# DA1470x register map
Vendor: Dialog; Series: DA1470x; File version: 1.2
CPU: CM33 r0p2, little endian, MPU, FPU, DSP, VTOR, 4 interrupt priority bits
Registers are 32-bit, read-write, reset 0x0 unless marked. A register's access mark holds for its fields unless they carry their own. Offsets are from the block's base; [hi:lo] are bit positions.

## GPREG — GPREG registers
Base 0x50040100
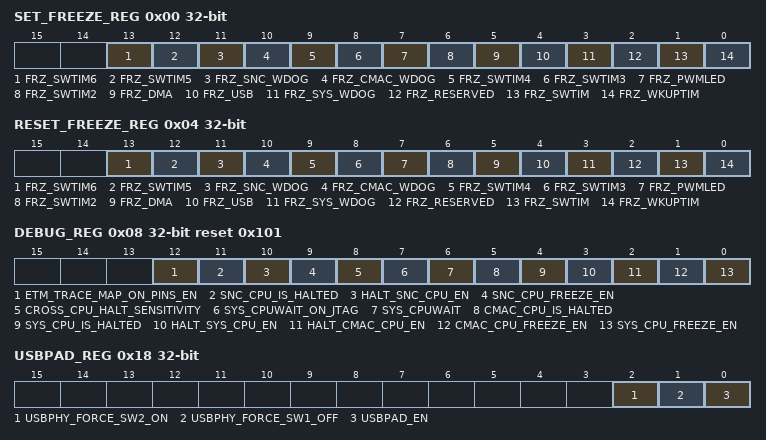
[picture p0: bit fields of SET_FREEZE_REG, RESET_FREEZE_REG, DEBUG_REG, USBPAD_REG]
0x00 SET_FREEZE_REG — Controls freezing of various timers/counters (incl. DMA and USB).
  [13] FRZ_SWTIM6 — If '1', the SW Timer6 is frozen, '0' is discarded.
  [12] FRZ_SWTIM5 — If '1', the SW Timer5 is frozen, '0' is discarded.
  [11] FRZ_SNC_WDOG — If '1', the SNC SW Watchdog Timer is frozen, '0' is discarded.
  [10] FRZ_CMAC_WDOG — If '1', the CMAC SW Watchdog Timer is frozen, '0' is discarded.
  [9] FRZ_SWTIM4 — If '1', the SW Timer4 is frozen, '0' is discarded.
  [8] FRZ_SWTIM3 — If '1', the SW Timer3 is frozen, '0' is discarded.
  [7] FRZ_PWMLED — If '1', the PWM LED is frozen, '0' is discarded.
  [6] FRZ_SWTIM2 — If '1', the SW Timer2 is frozen, '0' is discarded.
  [5] FRZ_DMA — If '1', the DMA is frozen, '0' is discarded.
  [4] FRZ_USB — If '1', the USB is frozen, '0' is discarded.
  [3] FRZ_SYS_WDOG — If '1', the SYS SW Watchdog Timer is frozen, '0' is discarded. WATCHDOG_CTRL_REG[NMI_RST] must be '0' to allow the freeze function.
  [2] FRZ_RESERVED
  [1] FRZ_SWTIM — If '1', the SW Timer is frozen, '0' is discarded.
  [0] FRZ_WKUPTIM — If '1', the Wake Up Timer is frozen, '0' is discarded.
0x04 RESET_FREEZE_REG — Controls unfreezing of various timers/counters (incl. DMA and USB).
  [13] FRZ_SWTIM6 — If '1', the SW Timer6 continues, '0' is discarded.
  [12] FRZ_SWTIM5 — If '1', the SW Timer5 continues, '0' is discarded.
  [11] FRZ_SNC_WDOG — If '1', the SNC SW Watchdog Timer continues, '0' is discarded.
  [10] FRZ_CMAC_WDOG — If '1', the CMAC SW Watchdog Timer continues, '0' is discarded.
  [9] FRZ_SWTIM4 — If '1', the SW Timer4 continues, '0' is discarded.
  [8] FRZ_SWTIM3 — If '1', the SW Timer3 continues, '0' is discarded.
  [7] FRZ_PWMLED — If '1', the PWM LED continues, '0' is discarded.
  [6] FRZ_SWTIM2 — If '1', the SW Timer2 continues, '0' is discarded.
  [5] FRZ_DMA — If '1', the DMA continues, '0' is discarded.
  [4] FRZ_USB — If '1', the USB continues, '0' is discarded.
  [3] FRZ_SYS_WDOG — If '1', the SYS SW Watchdog Timer continues, '0' is discarded.
  [2] FRZ_RESERVED
  [1] FRZ_SWTIM — If '1', the SW Timer continues, '0' is discarded.
  [0] FRZ_WKUPTIM — If '1', the Wake Up Timer continues, '0' is discarded.
0x08 DEBUG_REG reset 0x101 — Various debug information register.
  [12] ETM_TRACE_MAP_ON_PINS_EN — 1: ETM/TPIU Trace signals mapped on GPIO pins is enabled.
  [11] SNC_CPU_IS_HALTED ro — 1: SNC CPU is halted.
  [10] HALT_SNC_CPU_EN — 1: Enable halting the SNC CPU when the SYS CPU (ARM CM33) or CMAC CPU is halted. Note 1: This bit is retained. Note 2: Set this bit to '0' before going into deep sleep to prevent unpredictable halting behavior after waking up.
  [9] SNC_CPU_FREEZE_EN — 1: Enable Freezing on-chip peripherals (see Note 2) by the SNC CPU. Note 1: This bit is retained. Note 2: See [RE]SET_FREEZE_REG for the specific on-chip peripherals.
  [8] CROSS_CPU_HALT_SENSITIVITY — Select the cross CPU halt sensitivity. 0: Level triggered, 1: Pulse triggered. Note: This bit is retained.
  [7] SYS_CPUWAIT_ON_JTAG — 1: Stall the processor core out of reset (only after a wake-up from JTAG). Debugger access continue when the core is stalled. When set to '0' again the core resumes instruction execution. This feature is independent of the PDC (Power Domain Controller) settings. If this bit is set and there is SW/JTAG activity during deep sleep, the SYS CPU is stalled after the wake-up. Note: This bit is retained.
  [6] SYS_CPUWAIT — 1: Stall the processor core out of reset (always after a wake-up). Debugger access continue when the core is stalled. When set to '0' again the core resumes instruction execution. Note: This bit is retained.
  [5] CMAC_CPU_IS_HALTED ro — 1: CMAC CPU is halted.
  [4] SYS_CPU_IS_HALTED ro — 1: SYS CPU (ARM CM33) is halted.
  [3] HALT_SYS_CPU_EN — 1: Enable halting the SYS CPU (ARM CM33) when the CMAC CPU or SNC CPU is halted. Note 1: This bit is retained. Note 2: Set this bit to '0' before going into deep sleep to prevent unpredictable halting behavior after waking up.
  [2] HALT_CMAC_CPU_EN — 1: Enable halting the CMAC CPU when the SYS CPU (ARM CM33) or SNC CPU is halted. Note 1: This bit is retained. Note 2: Set this bit to '0' before going into deep sleep to prevent unpredictable halting behavior after waking up.
  [1] CMAC_CPU_FREEZE_EN — 1: Enable Freezing on-chip peripherals (see Note 2) by the CMAC CPU. Note 1: This bit is retained. Note 2: See [RE]SET_FREEZE_REG for the specific on-chip peripherals.
  [0] SYS_CPU_FREEZE_EN — 1: Enable Freezing on-chip peripherals (see Note 2) by the SYS CPU (ARM CM33). Default '1', freezing of the on-chip peripherals is enabled when the Cortex-M33 is halted in DEBUG State. If '0', freezing of the on-chip peripherals is only depending on [RE]SET_FREEZE_REG except the system watchdog timer. The system watchdog timer is always frozen when the Cortex-M33 is halted in DEBUG State. Note 1: This bit is retained. Note 2: See [RE]SET_FREEZE_REG for the specific on-chip peripherals.
0x0C GP_STATUS_REG — General purpose system status register.
  [0] CAL_PHASE — If '1', it designates that the chip is in Calibration Phase i.e. the OTP has been initially programmed but no Calibration has occured.
0x18 USBPAD_REG — USB pads control register
  [2] USBPHY_FORCE_SW2_ON — 0: Pull up resistor SW2 is controlled by the USB controller. It is off when the USB is not enabled. 1: Force the pull up resistor on USBP to be 2.3Kohm
  [1] USBPHY_FORCE_SW1_OFF — 0: Pull up resistor SW1 is controlled by the USB controller. It is off when the USB is not enabled. 1: Force the pull up resistor on USBP to be switched off.
  [0] USBPAD_EN — 0: The power for the USB PHY and USB pads is switched on when the USB is enabled. 1: The power for the USB PHY and USB pads is forced on.
